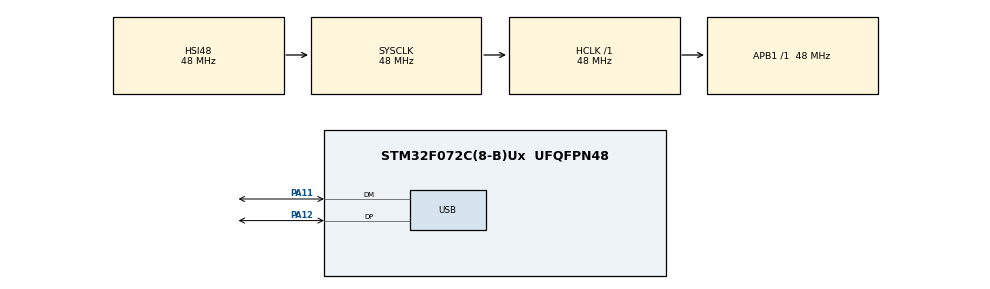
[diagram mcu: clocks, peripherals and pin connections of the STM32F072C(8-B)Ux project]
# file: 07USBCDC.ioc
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Mcu.Family=STM32F0
Mcu.Name=STM32F072C(8-B)Ux
Mcu.Package=UFQFPN48
NVIC.USB_IRQn=true\:0\:0\:false\:false\:true\:false\:true\:true
PA11.Mode=Device
PA11.Signal=USB_DM
PA12.Mode=Device
PA12.Signal=USB_DP
PA13.Mode=Serial_Wire
PA13.Signal=SYS_SWDIO
PA14.Mode=Serial_Wire
PA14.Signal=SYS_SWCLK
ProjectManager.HeapSize=0x200
ProjectManager.StackSize=0x400
ProjectManager.TargetToolchain=STM32CubeIDE
RCC.AHBFreq_Value=48000000
RCC.APB1Freq_Value=48000000
RCC.APB1TimFreq_Value=48000000
RCC.HCLKFreq_Value=48000000
RCC.SYSCLKFreq_VALUE=48000000
RCC.SYSCLKSource=RCC_SYSCLKSOURCE_HSI48
USB_DEVICE.CLASS_NAME_FS=CDC
USB_DEVICE.VirtualMode=Cdc
USB_DEVICE.VirtualModeFS=Cdc_FS
VP_RCC_USB.Mode=CRS SYNC Source USB
VP_USB_DEVICE_VS_USB_DEVICE_CDC_FS.Mode=CDC_FS
board=custom

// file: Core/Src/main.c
/* USER CODE BEGIN Header */
/**
  ******************************************************************************
  * @file           : main.c
  * @brief          : Main program body
  ******************************************************************************
  * @attention
  *
  * Copyright (c) 2026 STMicroelectronics.
  * All rights reserved.
  *
  * This software is licensed under terms that can be found in the LICENSE file
  * in the root directory of this software component.
  * If no LICENSE file comes with this software, it is provided AS-IS.
  *
  ******************************************************************************
  */
/* USER CODE END Header */
#include "main.h"
#include "usb_device.h"
#include "gpio.h"

/* USER CODE BEGIN Includes */
#include "usbd_cdc_if.h"
/*
 * USB CDC ACM 回显示例：PA11=USB_DM、PA12=USB_DP，USB 时钟必须保持 48 MHz，
 * 否则主机可能无法枚举。MX_USB_DEVICE_Init() 在外设时钟就绪后启动协议栈；
 * 主循环持续处理接收队列，不在 USB 回调中等待发送完成。
 */

/* USER CODE END Includes */

void SystemClock_Config(void);

int main(void)
{

  /* MCU Configuration--------------------------------------------------------*/

  /* Reset of all peripherals, Initializes the Flash interface and the Systick. */
  HAL_Init();

  /* Configure the system clock */
  SystemClock_Config();

  /* Initialize all configured peripherals */
  MX_GPIO_Init();
  MX_USB_DEVICE_Init();

  /* Infinite loop */
  while (1)
  {

    /* USER CODE BEGIN 3 */
    /*
     * USB CDC 回显业务轮询：收到的每个字节都会按原顺序发回主机。
     * 函数内部是非阻塞的，因此不要在这里增加 HAL_Delay()；调用越及时，
     * 越能承受主机连续发送的数据。如果以后加入其他业务，也应避免长时间阻塞。
     */
    CDC_EchoProcess_FS();
  }
  /* USER CODE END 3 */
}

void SystemClock_Config(void)
{
  RCC_OscInitTypeDef RCC_OscInitStruct = {0};
  RCC_ClkInitTypeDef RCC_ClkInitStruct = {0};
  RCC_PeriphCLKInitTypeDef PeriphClkInit = {0};
  RCC_CRSInitTypeDef RCC_CRSInitStruct = {0};

  /** Initializes the RCC Oscillators according to the specified parameters
  * in the RCC_OscInitTypeDef structure.
  */
  RCC_OscInitStruct.OscillatorType = RCC_OSCILLATORTYPE_HSI48;
  RCC_OscInitStruct.HSI48State = RCC_HSI48_ON;
  RCC_OscInitStruct.PLL.PLLState = RCC_PLL_NONE;
  if (HAL_RCC_OscConfig(&RCC_OscInitStruct) != HAL_OK)
  {
    Error_Handler();
  }

  /** Initializes the CPU, AHB and APB buses clocks
  */
  RCC_ClkInitStruct.ClockType = RCC_CLOCKTYPE_HCLK|RCC_CLOCKTYPE_SYSCLK
                              |RCC_CLOCKTYPE_PCLK1;
  RCC_ClkInitStruct.SYSCLKSource = RCC_SYSCLKSOURCE_HSI48;
  RCC_ClkInitStruct.AHBCLKDivider = RCC_SYSCLK_DIV1;
  RCC_ClkInitStruct.APB1CLKDivider = RCC_HCLK_DIV1;

  if (HAL_RCC_ClockConfig(&RCC_ClkInitStruct, FLASH_LATENCY_1) != HAL_OK)
  {
    Error_Handler();
  }
  PeriphClkInit.PeriphClockSelection = RCC_PERIPHCLK_USB;
  PeriphClkInit.UsbClockSelection = RCC_USBCLKSOURCE_HSI48;

  if (HAL_RCCEx_PeriphCLKConfig(&PeriphClkInit) != HAL_OK)
  {
    Error_Handler();
  }

  /** Enable the SYSCFG APB clock
  */
  __HAL_RCC_CRS_CLK_ENABLE();

  /** Configures CRS
  */
  RCC_CRSInitStruct.Prescaler = RCC_CRS_SYNC_DIV1;
  RCC_CRSInitStruct.Source = RCC_CRS_SYNC_SOURCE_USB;
  RCC_CRSInitStruct.Polarity = RCC_CRS_SYNC_POLARITY_RISING;
  RCC_CRSInitStruct.ReloadValue = __HAL_RCC_CRS_RELOADVALUE_CALCULATE(48000000,1000);
  RCC_CRSInitStruct.ErrorLimitValue = 34;
  RCC_CRSInitStruct.HSI48CalibrationValue = 32;

  HAL_RCCEx_CRSConfig(&RCC_CRSInitStruct);
}

void Error_Handler(void)
{
  __disable_irq();
  while (1)
  {
  }
}
